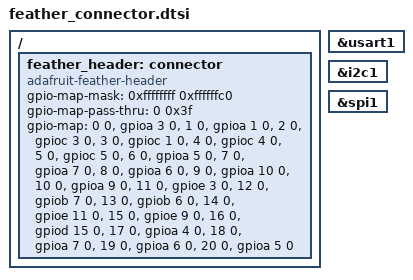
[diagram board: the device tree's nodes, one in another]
/*
 * Copyright (c) 2022 Blues Inc.
 *
 * SPDX-License-Identifier: Apache-2.0
 */

/ {
	feather_header: connector {
		compatible = "adafruit-feather-header";
		#gpio-cells = <2>;
		gpio-map-mask = <0xffffffff 0xffffffc0>;
		gpio-map-pass-thru = <0 0x3f>;
		gpio-map = <0 0 &gpioa 3 0>,	/* A0 */
			   <1 0 &gpioa 1 0>,	/* A1 */
			   <2 0 &gpioc 3 0>,	/* A2 */
			   <3 0 &gpioc 1 0>,	/* A3 */
			   <4 0 &gpioc 4 0>,	/* A4 */
			   <5 0 &gpioc 5 0>,	/* A5 */
			   <6 0 &gpioa 5 0>,	/* SCK */
			   <7 0 &gpioa 7 0>,	/* MOSI */
			   <8 0 &gpioa 6 0>,	/* MISO */
			   <9 0 &gpioa 10 0>,	/* RX */
			   <10 0 &gpioa 9 0>,	/* TX */
			   <11 0 &gpioe 3 0>,	/* D4 */
			   <12 0 &gpiob 7 0>,	/* SDA */
			   <13 0 &gpiob 6 0>,	/* SCL */
			   <14 0 &gpioe 11 0>,	/* D5 */
			   <15 0 &gpioe 9 0>,	/* D6 */
			   <16 0 &gpiod 15 0>,	/* D9 */
			   <17 0 &gpioa 4 0>,	/* D10 */
			   <18 0 &gpioa 7 0>,	/* D11 */
			   <19 0 &gpioa 6 0>,	/* D12 */
			   <20 0 &gpioa 5 0>;	/* D13 */
	};
};

feather_serial: &usart1 {};

feather_i2c: &i2c1 {};

feather_spi: &spi1 {};
